AUTOSAR XML (schema 00048)
package /ComponentTypes
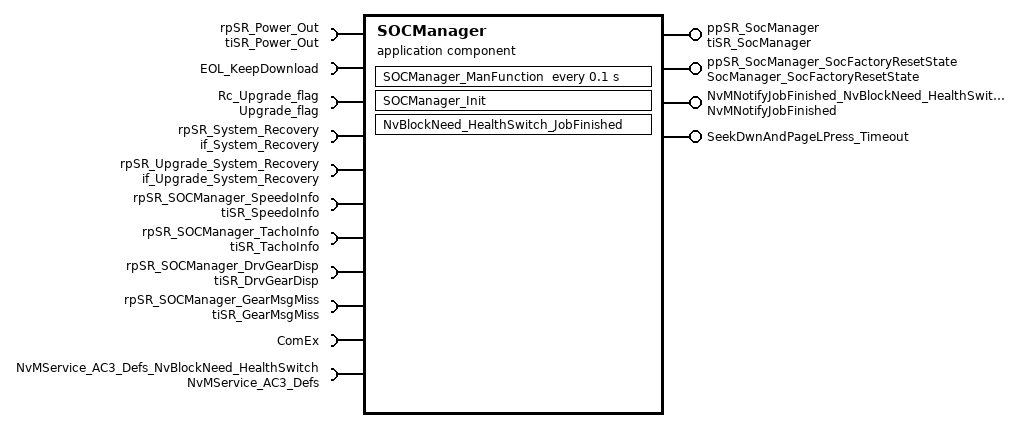
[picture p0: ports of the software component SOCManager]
  application sw component type SOCManager
    provide port ppSR_SocManager: nonqueued-sender-com-spec{data-element=SystemState, init-value=0}, provided-interface=tiSR_SocManager
    require port rpSR_Power_Out: nonqueued-receiver-com-spec{data-element=SystemStateOut, filter=data-filter-type=ALWAYS, init-value=constant-reference=PowerOutInit}, required-interface=tiSR_Power_Out
    require port EOL_KeepDownload: nonqueued-receiver-com-spec{data-element=keepDownloadRID, filter=data-filter-type=ALWAYS, init-value=0}, required-interface=EOL_KeepDownload
    provide port ppSR_SocManager_SocFactoryResetState: nonqueued-sender-com-spec=SocFactoryResetReady, provided-interface=SocManager_SocFactoryResetState
    9 x require port:
      Rc_Upgrade_flag: nonqueued-receiver-com-spec{data-element=Element, filter=data-filter-type=ALWAYS, init-value=0}, required-interface=Upgrade_flag
      rpSR_System_Recovery: nonqueued-receiver-com-spec{data-element=System_Recovery, filter=data-filter-type=ALWAYS, init-value=0}, required-interface=if_System_Recovery
      rpSR_Upgrade_System_Recovery: nonqueued-receiver-com-spec{data-element=System_Recovery, filter=data-filter-type=ALWAYS, init-value=0}, required-interface=if_Upgrade_System_Recovery
      rpSR_SOCManager_SpeedoInfo: nonqueued-receiver-com-spec{data-element=Element, filter=data-filter-type=ALWAYS, init-value=fields=[OverSpdWrnFlg:0, VehRunSts:0, IndicateSpeed:0, RealSpeed:0, IndicateSpeedMile:0, RealSpeedMile:0, RealSpeedBak:0, Msg_missingSts:0, VehSpdVld:0]}, required-interface=tiSR_SpeedoInfo
      rpSR_SOCManager_TachoInfo: nonqueued-receiver-com-spec{data-element=Element, filter=data-filter-type=ALWAYS, init-value=fields=[EngRunSts:0, EngSpd:0, TimeOutFlag:0, EngSpdBak:0, Msg_missingSts:0]}, required-interface=tiSR_TachoInfo
      rpSR_SOCManager_DrvGearDisp: nonqueued-receiver-com-spec{data-element=Element, filter=data-filter-type=ALWAYS, init-value=0}, required-interface=tiSR_DrvGearDisp
      rpSR_SOCManager_GearMsgMiss: nonqueued-receiver-com-spec{data-element=Element, filter=data-filter-type=ALWAYS, init-value=0}, required-interface=tiSR_GearMsgMiss
      ComEx: required-com-specs=[SendSignal, ReceiveSignal, GetRxE2EStatus], required-interface=ComEx
      NvMService_AC3_Defs_NvBlockNeed_HealthSwitch: required-com-specs=[WriteBlock, RestoreBlockDefaults, ReadBlock, InvalidateNvBlock, GetErrorStatus, EraseBlock], required-interface=NvMService_AC3_Defs
    provide port NvMNotifyJobFinished_NvBlockNeed_HealthSwitch: server-com-spec{operation=JobFinished, queue-length=1}, provided-interface=NvMNotifyJobFinished
    provide port SeekDwnAndPageLPress_Timeout: nonqueued-sender-com-spec{data-element=Element, init-value=0}, provided-interface=SeekDwnAndPageLPress_Timeout
    behavior SOCManager_InternalBehavior
      exclusive area ExclusiveArea_SOCManager
      ar-typed-per-instance-memorys:
        data NvBlockNeed_HealthSwitch_MirrorBlock: sw-calibration-access=READ-ONLY, type=uint8
      init event SOCManager_InitEvent: start-on-event=SOCManager_Init
      timing event TMT_SOCManager_ManFunction: start-on-event=SOCManager_ManFunction, period=0.1
      operation invoked event OIT_NvBlockNeed_HealthSwitch_JobFinished_NvMNotifyJobFinished_NvBlockNeed_HealthSwitch_JobFinished: start-on-event=NvBlockNeed_HealthSwitch_JobFinished, operation=NvMNotifyJobFinished_NvBlockNeed_HealthSwitch.JobFinished
      runnable SOCManager_ManFunction: can-enter-exclusive-area=ExclusiveArea_SOCManager
        data-receive-point-by-arguments:
          9 x access:
            REC_EOL_KeepDownload_keepDownloadRID: accessed-variable=EOL_KeepDownload.keepDownloadRID
            REC_Rc_Upgrade_flag_Element: accessed-variable=Rc_Upgrade_flag.Element
            REC_rpSR_System_Recovery_System_Recovery: accessed-variable=rpSR_System_Recovery.System_Recovery
            REC_rpSR_Upgrade_System_Recovery_System_Recovery: accessed-variable=rpSR_Upgrade_System_Recovery.System_Recovery
            REC_rpSR_SOCManager_SpeedoInfo_Element: accessed-variable=rpSR_SOCManager_SpeedoInfo.Element
            REC_rpSR_SOCManager_TachoInfo_Element: accessed-variable=rpSR_SOCManager_TachoInfo.Element
            REC_rpSR_SOCManager_DrvGearDisp_Element: accessed-variable=rpSR_SOCManager_DrvGearDisp.Element
            REC_rpSR_SOCManager_GearMsgMiss_Element: accessed-variable=rpSR_SOCManager_GearMsgMiss.Element
            REC_rpSR_Power_Out_SystemStateOut: accessed-variable=rpSR_Power_Out.SystemStateOut
        data-send-points:
          access SEND_ppSR_SocManager_SystemState: accessed-variable=ppSR_SocManager.SystemState
          access SEND_ppSR_SocManager_SocFactoryResetState_SocFactoryResetReady: accessed-variable=ppSR_SocManager_SocFactoryResetState.SocFactoryResetReady
          access SEND_SeekDwnAndPageLPress_Timeout_Element: accessed-variable=SeekDwnAndPageLPress_Timeout.Element
        9 x sync call:
          SC_ComEx_GetRxE2EStatus: operation=ComEx.GetRxE2EStatus
          SC_ComEx_ReceiveSignal: operation=ComEx.ReceiveSignal
          SC_ComEx_SendSignal: operation=ComEx.SendSignal
          SC_NvMService_AC3_Defs_NvBlockNeed_HealthSwitch_EraseBlock: operation=NvMService_AC3_Defs_NvBlockNeed_HealthSwitch.EraseBlock
          SC_NvMService_AC3_Defs_NvBlockNeed_HealthSwitch_GetErrorStatus: operation=NvMService_AC3_Defs_NvBlockNeed_HealthSwitch.GetErrorStatus
          SC_NvMService_AC3_Defs_NvBlockNeed_HealthSwitch_InvalidateNvBlock: operation=NvMService_AC3_Defs_NvBlockNeed_HealthSwitch.InvalidateNvBlock
          SC_NvMService_AC3_Defs_NvBlockNeed_HealthSwitch_ReadBlock: operation=NvMService_AC3_Defs_NvBlockNeed_HealthSwitch.ReadBlock
          SC_NvMService_AC3_Defs_NvBlockNeed_HealthSwitch_RestoreBlockDefaults: operation=NvMService_AC3_Defs_NvBlockNeed_HealthSwitch.RestoreBlockDefaults
          SC_NvMService_AC3_Defs_NvBlockNeed_HealthSwitch_WriteBlock: operation=NvMService_AC3_Defs_NvBlockNeed_HealthSwitch.WriteBlock
      runnable SOCManager_Init
      runnable NvBlockNeed_HealthSwitch_JobFinished
      swc service dependency NvBlockNeed_HealthSwitch
        assigned-datas:
          role=ramBlock, used-data-element=NvBlockNeed_HealthSwitch_MirrorBlock
          role=defaultValue, used-parameter-element=NvBlockNeed_HealthSwitch_DefaultValue
        assigned-ports:
          port-prototype=NvMService_AC3_Defs_NvBlockNeed_HealthSwitch, role=NvMService_AC3_Defs
          port-prototype=NvMNotifyJobFinished_NvBlockNeed_HealthSwitch, role=NvMNotifyJobFinished
        service-needs:
          nv block needs NvBlockNeed_HealthSwitch: n-data-sets=0, ram-block-status-control=API, reliability=NO-PROTECTION
      shared-parameters:
        parameter data prototype NvBlockNeed_HealthSwitch_DefaultValue: sw-calibration-access=READ-WRITE, type=uint8, init-value=1
  swc implementation SOCManager_Implementation: behavior=SOCManager_InternalBehavior
